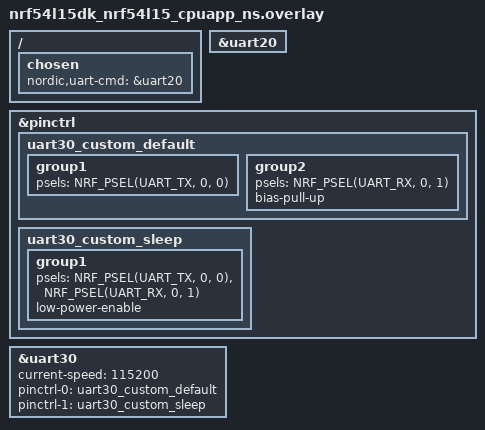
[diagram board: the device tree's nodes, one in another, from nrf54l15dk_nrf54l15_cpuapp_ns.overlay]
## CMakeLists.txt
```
#
# Copyright (c) 2019 Nordic Semiconductor ASA
#
# SPDX-License-Identifier: LicenseRef-Nordic-5-Clause
#
cmake_minimum_required(VERSION 3.20.0)

find_package(Zephyr REQUIRED HINTS $ENV{ZEPHYR_BASE})
project(mesh_shell)

include_directories(${ZEPHYR_NRF_MODULE_DIR}/samples/bluetooth/mesh/common)

# NORDIC SDK APP START
target_sources(app PRIVATE
  src/main.c
  src/model_handler.c
)
target_include_directories(app PRIVATE
  include
  ${ZEPHYR_NRF_MODULE_DIR}/samples/bluetooth/mesh/common
)

# Preinitialization related to DFU over SMP
target_sources_ifdef(CONFIG_MCUMGR_TRANSPORT_BT app PRIVATE
  ${ZEPHYR_NRF_MODULE_DIR}/samples/bluetooth/mesh/common/smp_bt.c
)

# NORDIC SDK APP END
```

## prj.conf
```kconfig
CONFIG_TEST=y
CONFIG_TEST_LOGGING_DEFAULTS=n
#CONFIG_INIT_STACKS=y
CONFIG_MAIN_STACK_SIZE=1024
CONFIG_ISR_STACK_SIZE=2048
CONFIG_SYSTEM_WORKQUEUE_STACK_SIZE=8192
CONFIG_SHELL_STACK_SIZE=2048

CONFIG_SHELL=y
CONFIG_SHELL_CMD_BUFF_SIZE=128
CONFIG_SHELL_BACKEND_SERIAL=y
CONFIG_SHELL_BACKEND_SERIAL_API_ASYNC=n
CONFIG_SHELL_BACKEND_SERIAL_API_INTERRUPT_DRIVEN=y
CONFIG_UART_INTERRUPT_DRIVEN=y


# Dummy backend to capture shell output
CONFIG_SHELL_BACKEND_DUMMY=y
CONFIG_SHELL_BACKEND_DUMMY_BUF_SIZE=1024

# Use RTT for logging and shell
CONFIG_USE_SEGGER_RTT=y
CONFIG_RTT_CONSOLE=y
CONFIG_UART_CONSOLE=n
CONFIG_SHELL_BACKEND_SERIAL=n
CONFIG_SHELL_BACKEND_RTT=y
CONFIG_LOG_BACKEND_RTT=y
CONFIG_LOG_BACKEND_UART=n
# Use different RTT channels for shell and log
CONFIG_SHELL_BACKEND_RTT_BUFFER=0
CONFIG_LOG_BACKEND_RTT_BUFFER=1

CONFIG_BT_SETTINGS=y
CONFIG_FLASH=y
CONFIG_FLASH_MAP=y
CONFIG_NVS=y
CONFIG_SETTINGS=y
# CONFIG_SECURE_STORAGE=y

CONFIG_BT=y
CONFIG_BT_OBSERVER=y
CONFIG_BT_PERIPHERAL=y
CONFIG_BT_DEVICE_NAME="Zephyr Mesh"
CONFIG_BT_GATT_CACHING=n

CONFIG_BT_CTLR_LE_ENC=n
CONFIG_BT_CTLR_LE_PING=n
CONFIG_BT_DATA_LEN_UPDATE=n
CONFIG_BT_PHY_UPDATE=n
CONFIG_BT_CTLR_MIN_USED_CHAN=n
CONFIG_BT_CTLR_PRIVACY=n
CONFIG_BT_CTLR_DTM_HCI=n
CONFIG_BT_CTLR_EXT_SCAN_FP=n
CONFIG_BT_DATA_LEN_UPDATE=n
CONFIG_BT_CTLR_PER_INIT_FEAT_XCHG=n
#CONFIG_BT_CTLR_ADVANCED_FEATURES=y
CONFIG_BT_CTLR_FILTER_ACCEPT_LIST=n

CONFIG_BT_L2CAP_TX_BUF_COUNT=4

CONFIG_BT_MESH=y
CONFIG_BT_MESH_SHELL=y
CONFIG_BT_MESH_SHELL_HEALTH_SRV_INSTANCE=y
CONFIG_BT_MESH_SHELL_PROV_CTX_INSTANCE=y
CONFIG_BT_MESH_RELAY=y
CONFIG_BT_MESH_LOW_POWER=n
CONFIG_BT_MESH_LPN_AUTO=n
CONFIG_BT_MESH_FRIEND=y
CONFIG_BT_MESH_FRIEND_QUEUE_SIZE=16
CONFIG_BT_MESH_ADV_BUF_COUNT=9
CONFIG_BT_MESH_CFG_CLI=y
CONFIG_BT_MESH_CFG_CLI_TIMEOUT=6000
CONFIG_BT_MESH_HEALTH_CLI=y
CONFIG_BT_MESH_TX_SEG_MSG_COUNT=2
CONFIG_BT_MESH_RX_SEG_MSG_COUNT=2
CONFIG_BT_MESH_RX_SEG_MAX=32
CONFIG_BT_MESH_TX_SEG_MAX=32
CONFIG_BT_MESH_CRPL=128

CONFIG_BT_MESH_PB_GATT=y
CONFIG_BT_MESH_PB_ADV=y
CONFIG_BT_MESH_GATT_PROXY=y
CONFIG_BT_MESH_NODE_ID_TIMEOUT=10

CONFIG_BT_MESH_APP_KEY_COUNT=10
# PTS requires more key slots when using Opcodes Aggregator.
# First one is implicitly taken by Device Key.
CONFIG_BT_MESH_MODEL_KEY_COUNT=10
CONFIG_BT_MESH_MODEL_GROUP_COUNT=2
CONFIG_BT_MESH_LABEL_COUNT=1

CONFIG_LOG=y
CONFIG_LOG_BUFFER_SIZE=4096
CONFIG_LOG_PROCESS_THREAD_SLEEP_MS=100
CONFIG_LOG_MODE_DEFERRED=y

CONFIG_BT_MESH_IV_UPDATE_TEST=y
CONFIG_BT_MESH_LOG_LEVEL_DBG=y
CONFIG_BT_MESH_CDB=y
CONFIG_BT_MESH_CDB_SUBNET_COUNT=10
CONFIG_BT_MESH_CDB_APP_KEY_COUNT=15
CONFIG_BT_MESH_CDB_NODE_COUNT=128
CONFIG_BT_MESH_PROVISIONER=y
CONFIG_BT_MESH_STATISTIC=y

#Added includes
CONFIG_DK_LIBRARY=y
CONFIG_BT_MESH_ONOFF_SRV=y
CONFIG_BT_MESH_ONOFF_CLI=y


#for UART
CONFIG_SERIAL=y
# UART30 for board-to-board command reception (UART20 is console)

# Redirect TF-M to use UART20 (shared with console), freeing UART30 for application
CONFIG_TFM_SECURE_UART20=y
CONFIG_TFM_SECURE_UART30=n
CONFIG_NRF_UARTE30_SECURE=n
CONFIG_UART_30_INTERRUPT_DRIVEN=y
```

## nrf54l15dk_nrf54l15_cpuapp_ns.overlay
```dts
/*
 * UART30 overlay for board-to-board command communication
 * Keep UART20 for console/debug
 * Hardware flow control (RTS/CTS) disabled for simple 2-wire UART
 */

 &uart20{
	status = "okay";
 };

&pinctrl {
	uart30_custom_default: uart30_custom_default {
		group1 {
			psels = <NRF_PSEL(UART_TX, 0, 0)>;
		};
		group2 {
			psels = <NRF_PSEL(UART_RX, 0, 1)>;
			bias-pull-up;
		};
	};

	uart30_custom_sleep: uart30_custom_sleep {
		group1 {
			psels = <NRF_PSEL(UART_TX, 0, 0)>,
				<NRF_PSEL(UART_RX, 0, 1)>;
			low-power-enable;
		};
	};
};

&uart30 {
	status = "okay";
	current-speed = <115200>;
	pinctrl-0 = <&uart30_custom_default>;
	pinctrl-1 = <&uart30_custom_sleep>;
	pinctrl-names = "default", "sleep";
};

/ {
	chosen {
		nordic,uart-cmd = &uart20;
	};
};
```

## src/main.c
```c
/*
 * Copyright (c) 2017 Intel Corporation
 *
 * SPDX-License-Identifier: Apache-2.0
 */

#include <zephyr/sys/printk.h>
#include <zephyr/console/console.h>
#include <zephyr/kernel.h>
#include <zephyr/bluetooth/bluetooth.h>
#include <bluetooth/mesh/models.h>
#include <bluetooth/mesh/dk_prov.h>
#include <dk_buttons_and_leds.h>
#include <zephyr/shell/shell.h>
#include <zephyr/shell/shell_uart.h>
#include <zephyr/shell/shell_dummy.h>
#include <zephyr/bluetooth/mesh/shell.h>
#include "model_handler.h"
#include "init.h"
#include "uart_cmd.h"
#include "log_capture.h"
//#include "filtering.h"
#include "smp_bt.h"

/*ADDED INCLUDES*/
#include <zephyr/settings/settings.h>
#include <zephyr/drivers/uart.h>
#include <zephyr/logging/log_backend.h>
#include <zephyr/logging/log_output.h>
#include <zephyr/logging/log_ctrl.h>
#include <zephyr/sys/ring_buffer.h>
#include <string.h>
#include <stdio.h>

#if defined(CONFIG_SETTINGS)
#include <zephyr/settings/settings.h>
#endif



int main(void)
{
    int err;
    printk("Initializing...\n");
    err = bt_enable(bt_ready);
    if (err && err != -EALREADY) {
        printk("Bluetooth init failed (err %d)\n", err);
    }
    err = uart_cmd_init();
    if (err) {
        printk("UART command init failed (err %d)\n", err);
    }
    log_capture_init();
    printk("Press the <Tab> button for supported commands.\n");
    printk("Before any Mesh commands you must run \"mesh init\"\n");
    printk("Ready to receive commands via UART...\n");
    while (1) {
        k_sleep(K_FOREVER);
    }
    return 0;
}
```

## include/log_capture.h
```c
#ifndef LOG_CAPTURE_H
#define LOG_CAPTURE_H

#include <zephyr/sys/ring_buffer.h>
#include <zephyr/logging/log_backend.h>
#include <stddef.h>
#include <stdint.h>
#include <stdbool.h>

#ifdef __cplusplus
extern "C" {
#endif

bool log_capture_has_logs(void);
void log_capture_init(void);
void log_capture_enable(bool enable);
size_t strip_ansi_escapes(const char *src, size_t src_len, char *dst, size_t dst_size);
void log_backend_capture_init(const struct log_backend *const backend);
bool log_capture_has_logs(void);

#ifdef __cplusplus
}
#endif

#endif // LOG_CAPTURE_H
```

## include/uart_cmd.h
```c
#ifndef UART_CMD_H
#define UART_CMD_H

#include <zephyr/drivers/uart.h>
#include <zephyr/kernel.h>

#ifdef __cplusplus
extern "C" {
#endif

void uart_cmd_buffer_init(const struct device *uart_dev);
void uart_cmd_receive_char(uint8_t c);
void uart_cmd_process(void);
void uart30_send(const char *data, const char *subject);


#ifdef __cplusplus
}
#endif

#endif // UART_CMD_H
```

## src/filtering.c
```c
/* Filtering the data received on the UART30*/
/* Strip ANSI escape sequences and shell prompt from a buffer */
static size_t strip_ansi_escapes(const char *src, size_t src_len, char *dst, size_t dst_size)
{
	size_t dst_pos = 0;
	size_t i = 0;

	while (i < src_len && dst_pos < dst_size - 1) {
		/* Check for ESC character (0x1B) */
		if (src[i] == 0x1b) {
			i++;
			if (i < src_len && src[i] == '[') {
				/* CSI sequence: skip until we hit a letter (0x40-0x7E) */
				i++;
				while (i < src_len && (src[i] < 0x40 || src[i] > 0x7E)) {
					i++;
				}
				if (i < src_len) {
					i++; /* Skip the final character */
				}
			}
			/* Other escape types - just skip the ESC */
		} else if (src[i] == '~' && i + 2 < src_len && src[i+1] == '$' && src[i+2] == ' ') {
			/* Skip shell prompt "~$ " */
			i += 3;
		} else if (src[i] == '\r') {
			/* Skip carriage return */
			i++;
		} else {
			dst[dst_pos++] = src[i++];
		}
	}
	dst[dst_pos] = '\0';
	return dst_pos;
}
```

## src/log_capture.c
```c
#include "log_capture.h"
#include <zephyr/sys/ring_buffer.h>
#include <stdbool.h>
#include <stddef.h>
#include <stdint.h>
#include <string.h>

#define LOG_CAPTURE_BUF_SIZE 256
static uint8_t log_capture_buffer[LOG_CAPTURE_BUF_SIZE];
static struct ring_buf log_ringbuf;
static bool log_capture_enabled = false;

bool log_capture_has_logs(void) {
    return ring_buf_size_get(&log_ringbuf) > 0;
}

void log_capture_init(void) {
    ring_buf_init(&log_ringbuf, LOG_CAPTURE_BUF_SIZE, log_capture_buffer);
    log_capture_enabled = false;
}

void log_capture_enable(bool enable) {
    log_capture_enabled = enable;
}

// Log backend API callback for Zephyr logging system
void log_backend_capture_init(const struct log_backend *const backend) {
    ARG_UNUSED(backend);
    log_capture_init();
}

size_t strip_ansi_escapes(const char *src, size_t src_len, char *dst, size_t dst_size) {
    size_t dst_pos = 0;
    size_t i = 0;
    while (i < src_len && dst_pos < dst_size - 1) {
        if (src[i] == 0x1b) {
            i++;
            if (i < src_len && src[i] == '[') {
                i++;
                while (i < src_len && ((src[i] < '@' || src[i] > '~'))) {
                    i++;
                }
                if (i < src_len) i++;
            }
        } else if (src[i] == '~' && i + 2 < src_len && src[i+1] == '$' && src[i+2] == ' ') {
            i += 3;
        } else if (src[i] == '\r') {
            i++;
        } else {
            dst[dst_pos++] = src[i++];
        }
    }
    dst[dst_pos] = '\0';
    return dst_pos;
}
```

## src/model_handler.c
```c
#include <zephyr/bluetooth/bluetooth.h>
#include <bluetooth/mesh/models.h>
#include <bluetooth/mesh/gen_onoff_cli.h>
#include <errno.h>
#include <stdio.h>
#include <zephyr/sys/printk.h>
#include "uart_cmd.h"

/*ADDED INCLUDES*/
#include <zephyr/shell/shell.h>
#include <zephyr/bluetooth/mesh/shell.h>

static struct bt_mesh_cfg_cli cfg_cli;

static void OnOff_status_cb(struct bt_mesh_onoff_cli *cli,
                            struct bt_mesh_msg_ctx *ctx,
                            const struct bt_mesh_onoff_status *status)
{
	(void)cli;

	if (!ctx || !status) {
		printk("OnOff status callback received invalid data\n");
		return;
	}

	printk("OnOff status from 0x%04x: status=%u",
	       ctx->addr,
	       status->present_on_off ? 1U : 0U);

	if (status->remaining_time >= 0) {
		printk(", target=%u, remaining=%ld ms",
		       status->target_on_off ? 1U : 0U,
		       (long)status->remaining_time);
	}

	printk("\n");

	char status_msg[96];
	snprintf(status_msg, sizeof(status_msg),
	         "src=0x%04x status=%s",
	         ctx->addr,
	         status->present_on_off ? "ON" : "OFF");
	uart30_send(status_msg, "OnOff_status");
}

static struct bt_mesh_onoff_cli onoff_cli = BT_MESH_ONOFF_CLI_INIT(OnOff_status_cb);

#if defined(CONFIG_BT_MESH_DFD_SRV)
static struct bt_mesh_dfd_srv dfd_srv;
#endif

#if defined(CONFIG_BT_MESH_SAR_CFG_CLI)
static struct bt_mesh_sar_cfg_cli sar_cfg_cli;
#endif

#if defined(CONFIG_BT_MESH_PRIV_BEACON_CLI)
static struct bt_mesh_priv_beacon_cli priv_beacon_cli;
#endif

#if defined(CONFIG_BT_MESH_SOL_PDU_RPL_CLI)
static struct bt_mesh_sol_pdu_rpl_cli srpl_cli;
#endif


#if defined(CONFIG_BT_MESH_OD_PRIV_PROXY_CLI)
static struct bt_mesh_od_priv_proxy_cli od_priv_proxy_cli;
#endif

#if defined(CONFIG_BT_MESH_LARGE_COMP_DATA_CLI)
struct bt_mesh_large_comp_data_cli large_comp_data_cli;
#endif

#if defined(CONFIG_BT_MESH_BRG_CFG_CLI)
static struct bt_mesh_brg_cfg_cli brg_cfg_cli;
#endif

BT_MESH_SHELL_HEALTH_PUB_DEFINE(health_pub);

static const struct bt_mesh_model root_models[] = {
	BT_MESH_MODEL_CFG_SRV,
	BT_MESH_MODEL_CFG_CLI(&cfg_cli),
	BT_MESH_MODEL_ONOFF_CLI(&onoff_cli),
	BT_MESH_MODEL_HEALTH_SRV(&bt_mesh_shell_health_srv, &health_pub, health_srv_meta),
	BT_MESH_MODEL_HEALTH_CLI(&bt_mesh_shell_health_cli),
#if defined(CONFIG_BT_MESH_DFD_SRV)
	BT_MESH_MODEL_DFD_SRV(&dfd_srv),
#else
#if defined(CONFIG_BT_MESH_SHELL_DFU_SRV)
	BT_MESH_MODEL_DFU_SRV(&bt_mesh_shell_dfu_srv),
#elif defined(CONFIG_BT_MESH_SHELL_BLOB_SRV)
	BT_MESH_MODEL_BLOB_SRV(&bt_mesh_shell_blob_srv),
#endif
#if defined(CONFIG_BT_MESH_SHELL_DFU_CLI)
	BT_MESH_MODEL_DFU_CLI(&bt_mesh_shell_dfu_cli),
#elif defined(CONFIG_BT_MESH_SHELL_BLOB_CLI)
	BT_MESH_MODEL_BLOB_CLI(&bt_mesh_shell_blob_cli),
#endif
#endif /* CONFIG_BT_MESH_DFD_SRV */
#if defined(CONFIG_BT_MESH_SHELL_RPR_CLI)
	BT_MESH_MODEL_RPR_CLI(&bt_mesh_shell_rpr_cli),
#endif
#if defined(CONFIG_BT_MESH_RPR_SRV)
	BT_MESH_MODEL_RPR_SRV,
#endif

#if defined(CONFIG_BT_MESH_SAR_CFG_SRV)
	BT_MESH_MODEL_SAR_CFG_SRV,
#endif
#if defined(CONFIG_BT_MESH_SAR_CFG_CLI)
	BT_MESH_MODEL_SAR_CFG_CLI(&sar_cfg_cli),
#endif

#if defined(CONFIG_BT_MESH_OP_AGG_SRV)
	BT_MESH_MODEL_OP_AGG_SRV,
#endif
#if defined(CONFIG_BT_MESH_OP_AGG_CLI)
	BT_MESH_MODEL_OP_AGG_CLI,
#endif

#if defined(CONFIG_BT_MESH_LARGE_COMP_DATA_SRV)
	BT_MESH_MODEL_LARGE_COMP_DATA_SRV,
#endif
#if defined(CONFIG_BT_MESH_LARGE_COMP_DATA_CLI)
	BT_MESH_MODEL_LARGE_COMP_DATA_CLI(&large_comp_data_cli),
#endif

#if defined(CONFIG_BT_MESH_PRIV_BEACON_SRV)
	BT_MESH_MODEL_PRIV_BEACON_SRV,
#endif
#if defined(CONFIG_BT_MESH_PRIV_BEACON_CLI)
	BT_MESH_MODEL_PRIV_BEACON_CLI(&priv_beacon_cli),
#endif
#if defined(CONFIG_BT_MESH_OD_PRIV_PROXY_CLI)
	BT_MESH_MODEL_OD_PRIV_PROXY_CLI(&od_priv_proxy_cli),
#endif
#if defined(CONFIG_BT_MESH_SOL_PDU_RPL_CLI)
	BT_MESH_MODEL_SOL_PDU_RPL_CLI(&srpl_cli),
#endif
#if defined(CONFIG_BT_MESH_OD_PRIV_PROXY_SRV)
	BT_MESH_MODEL_OD_PRIV_PROXY_SRV,
#endif
#if defined(CONFIG_BT_MESH_BRG_CFG_SRV)
	BT_MESH_MODEL_BRG_CFG_SRV,
#endif
#if defined(CONFIG_BT_MESH_BRG_CFG_CLI)
	BT_MESH_MODEL_BRG_CFG_CLI(&brg_cfg_cli),
#endif
};

static const struct bt_mesh_elem elements[] = {
	BT_MESH_ELEM(0, root_models, BT_MESH_MODEL_NONE),
};


static const struct bt_mesh_comp comp = {
	.cid = CONFIG_BT_COMPANY_ID,
	.elem = elements,
	.elem_count = ARRAY_SIZE(elements),
};

const struct bt_mesh_comp *model_handler_init(void)
{
	return &comp;
}

int model_handler_onoff_set(uint16_t net_idx, uint16_t app_idx, uint16_t dst_addr, bool on_off)
{
	struct bt_mesh_msg_ctx ctx = {
		.net_idx = net_idx,
		.app_idx = app_idx,
		.addr = dst_addr,
		.send_ttl = BT_MESH_TTL_DEFAULT,
	};
	struct bt_mesh_onoff_set set = {
		.on_off = on_off,
		.reuse_transaction = false,
		.transition = NULL,
	};

	if (!bt_mesh_is_provisioned()) {
		return -EAGAIN;
	}

	return bt_mesh_onoff_cli_set_unack(&onoff_cli, &ctx, &set);
}
```

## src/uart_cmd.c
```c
#include "uart_cmd.h"
//#include <_mingw_stat64.h>
#include <stdbool.h>
#include <stdint.h> //vet ikke om trengs
#include <zephyr/kernel.h>
#include <zephyr/drivers/uart.h>
#include <zephyr/sys/printk.h>
#include <zephyr/shell/shell.h>
#include <zephyr/shell/shell_dummy.h>
#include <string.h>
#include <stdio.h>
#include "log_capture.h"
#include "model_handler.h"

//kanskje
#include <zephyr/bluetooth/mesh.h>
#if defined(CONFIG_BT_MESH_SHELL)
#include <zephyr/bluetooth/mesh/shell.h>
#endif


#define CMD_BUFFER_SIZE 128
#define CMD_QUEUE_LEN   32
#define RX_CMD_QUEUE_LEN 32
#define ONOFF_STATUS_GROUP_ADDR 0xC000
//static char *cmd_buffer[CMD_BUFFER_SIZE];
//static int *cmd_buffer_pos = 0;
//static K_SEM_DEFINE(cmd_sem, 0, 1);
//static K_SEM_DEFINE(cmd_count_sem, 0, CMD_BUFFER_SIZE);
static const struct device *uart_dev;
K_MSGQ_DEFINE(cmd_msgq, CMD_BUFFER_SIZE, CMD_QUEUE_LEN, 4);
K_MSGQ_DEFINE(rx_cmd_msgq, CMD_BUFFER_SIZE, RX_CMD_QUEUE_LEN, 4);

static const char *commands[] = {
    "init", // format: init
    "scan", // format: scan
    "provandconfig", // format: provandconfig <uuid> <net_idx> <app_idx>
    "light", // format: light_on <net_idx> <app_idx> <dst_addr> <on/off>
    "cdb", // format: cdb, Function for getting cdb show
    NULL
};

static char *uuids_cur_scan[32];
static int num_uuids_cur_scan = 0;

const uint16_t net_idx = 0x0000;
static uint16_t cur_app_idx = 0;
static uint16_t app_idx_list[10] = { [0 ... 9] = 0xFFFF}; //keep track of created app_idx for checking if app_idx exist when provisioning new devices, max 10 appkeys for simplicity
static int prov_count = 0x0001;
static uint16_t local_addr;


static void run_command(const char *command);
void uart30_send(const char *data, const char *subject);
static bool enqueue_command(const char *cmd); 

static void uuid_to_str(const uint8_t uuid[16], char *out, size_t out_len)
{
    static const char hex[] = "0123456789abcdef";
    size_t p = 0;

    for (size_t i = 0; i < 16 && (p + 2) < out_len; i++) {
        out[p++] = hex[(uuid[i] >> 4) & 0x0F];
        out[p++] = hex[uuid[i] & 0x0F];
    }

    if (p < out_len) {
        out[p] = '\0';
    } else if (out_len > 0) {
        out[out_len - 1] = '\0';
    }
}


static void uart_unprov_beacon_cb(const uint8_t uuid[16],
                                  bt_mesh_prov_oob_info_t oob_info,
                                  uint32_t *uri_hash){
    char uuid_str[33];
    char line[128];

    uuid_to_str(uuid, uuid_str, sizeof(uuid_str));

    printk("uuid=%s\r\n", uuid_str);

    for (int i = 0; i < num_uuids_cur_scan; i++) {
        if (strcmp(uuids_cur_scan[i], uuid_str) == 0) {
            return;
        }
    }
    if (num_uuids_cur_scan < 32) {
        uuids_cur_scan[num_uuids_cur_scan++] = strdup(uuid_str);
    }

    snprintf(line, sizeof(line), "%s", uuid_str);
    uart30_send(line, "UUID");
}

static void uart_node_added_cb(uint16_t net_idx,
                               const uint8_t uuid[16],
                               uint16_t addr,
                               uint8_t num_elem)
{
    char cmd[CMD_BUFFER_SIZE];
        snprintf(cmd, sizeof(cmd), "mesh target dst 0x%04x", addr);
        enqueue_command(cmd);
        snprintf(cmd, sizeof(cmd), "mesh target net %u", net_idx);
        enqueue_command(cmd);
        snprintf(cmd, sizeof(cmd), "mesh models cfg appkey add %u %u", net_idx, cur_app_idx);
        enqueue_command(cmd);
        for (int i = 0; i < num_elem; i++) {
            snprintf(cmd, sizeof(cmd), "mesh models cfg model app-bind 0x%04x %u 0x1000", addr + i, cur_app_idx);
            enqueue_command(cmd);
            /* Configure Generic OnOff Server publications to a shared group address. */
            snprintf(cmd, sizeof(cmd), "mesh models cfg model pub 0x%04x 0x1000 0x%04x %u 0 7 0 0 0 0", addr + i, ONOFF_STATUS_GROUP_ADDR, cur_app_idx);
            enqueue_command(cmd);
            prov_count += 1;
        }

        char response[128];
        snprintf(response, sizeof(response), "Binding complete on app_idx %u and net_idx %u on addresses 0x%04x-0x%04x", cur_app_idx, net_idx, addr, addr+num_elem-1);
        uart30_send(response, "Provisioning");
}

static bool enqueue_command(const char *cmd)
{
    if (!cmd || cmd[0] == '\0') {
        return false;
    }

    char tmp[CMD_BUFFER_SIZE];
    snprintf(tmp, sizeof(tmp), "%s", cmd);

    if (k_msgq_put(&cmd_msgq, tmp, K_NO_WAIT) != 0) {
        printk("Command queue full, dropping: %s\n", tmp);
        const char *response = "ERROR: Command queue full";
        uart30_send(response, "Error");
        return false;
    }
    return true;
}

size_t strip_ansi_escapes(const char *src, size_t src_len, char *dst, size_t dst_size) {
    size_t dst_pos = 0;
    size_t i = 0;
    while (i < src_len && dst_pos < dst_size - 1) {
        if (src[i] == 0x1b) {
            i++;
            if (i < src_len && src[i] == '[') {
                i++;
                while (i < src_len && ((src[i] < '@' || src[i] > '~'))) {
                    i++;
                }
                if (i < src_len) i++;
            }
        } else if (src[i] == '~' && i + 2 < src_len && src[i+1] == '$' && src[i+2] == ' ') {
            i += 3;
        } else if (src[i] == '\r') {
            i++;
        } else {
            dst[dst_pos++] = src[i++];
        }
    }
    dst[dst_pos] = '\0';
    return dst_pos;
}

void uart30_send(const char *data, const char *subject)
{
    if (!uart_dev || !device_is_ready(uart_dev)) {
        return;
    }
    char json_buf[1024];
    snprintf(json_buf, sizeof(json_buf), "%s %s",subject, data);
    size_t json_len = strip_ansi_escapes(json_buf, strlen(json_buf), json_buf, sizeof(json_buf));
    for (size_t i = 0; i < json_len; i++) {
        uart_poll_out(uart_dev, json_buf[i]);
        if(json_buf[i] == '\n') {
            for (int i = 0; i < strlen(subject); i++) {
                uart_poll_out(uart_dev, subject[i]);

            }
            uart_poll_out(uart_dev, ' ');
        }
    }
    uart_poll_out(uart_dev, '\n');
}

//receives uart commands from uart and runs them
static void uart_isr(const struct device *dev, void *user_data)
{
    ARG_UNUSED(user_data);

    static char uart_buffer[CMD_BUFFER_SIZE];
    static size_t uart_buffer_pos = 0;
    uint8_t c;
    if (!uart_irq_update(dev)) {
        return;
    }
    if (!uart_irq_rx_ready(dev)) {
        return;
    }
    while (uart_fifo_read(dev, &c, 1) == 1) {
        if (c == '\r' || c == '\n') {
            if (uart_buffer_pos > 0) {
                //check if the command is in the list of allowed commands
                //printk("Received command: %s\n", uart_buffer);
                //run_command(uart_buffer);
                (void)k_msgq_put(&rx_cmd_msgq, uart_buffer, K_NO_WAIT);
                uart_buffer_pos = 0;
                memset(uart_buffer, 0, sizeof(uart_buffer));
            }else {
                printk("Received empty command, ignoring\n");
            }

        } else if (uart_buffer_pos < CMD_BUFFER_SIZE - 1) {
            uart_buffer[uart_buffer_pos++] = (char)c;
            //printk("Received char: %c\n", c);
        } else {
            printk("Command buffer overflow, resetting\n");
            uart_buffer_pos = 0;
            memset(uart_buffer, 0, sizeof(uart_buffer));
        }
    }
}

void add_appkey(uint16_t app_idx, char app_key[32]) {

    enqueue_command("mesh target net 0");
    enqueue_command("mesh target dst local");
    char cmd[96];
    if (app_key && app_key[0] != '\0') {
        snprintf(cmd, sizeof(cmd), "mesh cdb app-key-add %u %u %s", net_idx, app_idx, app_key);
    } else {
        snprintf(cmd, sizeof(cmd), "mesh cdb app-key-add %u %u", net_idx, app_idx);
    }
    enqueue_command(cmd);
    snprintf(cmd, sizeof(cmd), "mesh models cfg appkey add %u %u", net_idx, app_idx);
    enqueue_command(cmd);
    snprintf(cmd, sizeof(cmd), "mesh models cfg model app-bind 0x%04x %u 0x1001", local_addr, app_idx);
    enqueue_command(cmd);
    //add appkey to list of app_idx
    for (int i = 0; i < ARRAY_SIZE(app_idx_list); i++) {
        if (app_idx_list[i] == 0xFFFF) {
            app_idx_list[i] = app_idx;
            break;
        }
    }
    
}


static void run_command(const char *command)
{
    static bool scanning = false;
    printk("received command: %s\n", command);
    if (strcmp(command, "init") == 0) {
        printk("Initializing device...\n");
        enqueue_command("mesh init");
        enqueue_command("mesh cdb create");
        app_idx_list[0] = 0;
        enqueue_command("mesh prov local 0 0x0001");
        local_addr = 0x0001;
        prov_count += 1;
        add_appkey(0, NULL);
        /* Subscribe local Generic OnOff Client to status publications. */
        char cmd[CMD_BUFFER_SIZE];
        snprintf(cmd, sizeof(cmd), "mesh models cfg model sub-add 0x%04x 0x%04x 0x1001", local_addr, ONOFF_STATUS_GROUP_ADDR);
        enqueue_command(cmd);
        bt_mesh_shell_prov.node_added = uart_node_added_cb;
        const char *response = "initialization complete";
        uart30_send(response, "init_complete");
    } else if (strcmp(command, "scan") == 0) {
        scanning = !scanning;
        if (scanning) {
            printk("Scanning for devices...\n");
            const char *response = "scan started";
            uart30_send(response, "response");
            num_uuids_cur_scan = 0; // Reset UUID list for new scan
            bt_mesh_shell_prov.unprovisioned_beacon = uart_unprov_beacon_cb;
        } else {
            printk("Stopping scan...\n");
            const char *response = "scan stopped";
            uart30_send(response, "response");
            bt_mesh_shell_prov.unprovisioned_beacon = NULL;
        }
    } else if (strncmp(command, "provandconfig", strlen("provandconfig")) == 0) {
        unsigned int net_idx = 0U, app_idx = 0U;
        char uuid[33];
        if (sscanf(command, "provandconfig %32s %u %u", uuid, &net_idx, &app_idx) != 3) {
            printk("wrong formating provandconfig, Usage: provandconfig <uuid> <net_idx> <app_idx>\n");
            char response[128];
            snprintf(response, sizeof(response), "wrong formating provandconfig, Usage: provandconfig <uuid> <net_idx> <app_idx>");
            uart30_send(response, "Error");
            return;
        }
        //check if app_idx exist
        bool app_idx_exists = false;
        for (int i = 0; i < ARRAY_SIZE(app_idx_list); i++) {
            if (app_idx_list[i] == app_idx) {
                app_idx_exists = true;
                break;
            }
        }
        if (!app_idx_exists) {
            printk("AppKey index %u does not exist, creating new", app_idx);
            add_appkey(app_idx, NULL);
        }
        cur_app_idx = app_idx;
        char cmd[CMD_BUFFER_SIZE];
        snprintf(cmd, sizeof(cmd),
                 "mesh prov remote-adv %s %u 0x%04x 5", uuid, net_idx, prov_count);
        enqueue_command(cmd);

        char response[128];
        snprintf(response, sizeof(response), "Provisioning started");
        uart30_send(response, "response");
    } else if (strncmp(command, "light", strlen("light")) == 0) {
        unsigned int net_idx = 0U, app_idx = 0U, dst_addr = 0U, on_off = 0U;
        if (sscanf(command, "light %u %u %u %u", &net_idx, &app_idx, &dst_addr, &on_off) != 4) {
            printk("wrong formating light command, Usage: light <net_idx> <app_idx> <dst_addr> <on/off>\n");
            char response[128];
            snprintf(response, sizeof(response), "wrong formating light command, Usage: light <net_idx> <app_idx> <dst_addr> <on/off>");
            uart30_send(response, "Error");
            return;
        }
        int err = model_handler_onoff_set((uint16_t)net_idx,
                                          (uint16_t)app_idx,
                                          (uint16_t)dst_addr,
                                          on_off != 0U);
        char response[128];
        if (err) {
            snprintf(response, sizeof(response), "Light command failed to 0x%04x (err %d)", dst_addr, err);
            uart30_send(response, "Error");
            return;
        }
        //snprintf(response, sizeof(response), "Light command sent to 0x%04x", dst_addr);
        //uart30_send(response, "response"); //response will be sent from onoff status callback when status is received
    }else if (strncmp(command, "cdb", strlen("cdb")) == 0) {
        enqueue_command("mesh cdb show");
    }else if (strncmp(command, "replace", strlen("replace")) == 0) {
        char netkey[33] = {0};
        if (sscanf(command, "replace netkey:%32s address:%hu", netkey, &local_addr) != 2) {
            printk("wrong formating replace command, Usage: replace netkey:<netkey> address:<addr>\n");
            char response[128];
            snprintf(response, sizeof(response), "wrong formating replace command, Usage: replace netkey:<netkey> address:<addr>");
            uart30_send(response, "Error");
            return;
        }
        prov_count = local_addr + 1;
        char cmd[100];
        enqueue_command("mesh init");
        snprintf(cmd, sizeof(cmd), "mesh cdb create %s", netkey);
        enqueue_command(cmd);
        snprintf(cmd, sizeof(cmd), "mesh prov local %u 0x%04x", net_idx, local_addr);
        enqueue_command(cmd);

        bt_mesh_shell_prov.node_added = uart_node_added_cb;

        
        // Subscribe local Generic OnOff Client to status publications
        snprintf(cmd, sizeof(cmd), "mesh models cfg model sub-add 0x%04x 0x%04x 0x1001", local_addr, ONOFF_STATUS_GROUP_ADDR);
        enqueue_command(cmd);


        uart30_send("reProvisioned", "reProvisioned");
    }
    else if (strncmp(command, "add appkey", strlen("add appkey")) == 0) {
        uint16_t app_idx = 0;
        char appkey[33];
        if (sscanf(command, "add appkey 0x%x %32s", &app_idx, appkey) != 2) {
            printk("wrong formating appkey command, Usage: add appkey <app_idx> <appkey>\n");
            char response[128];
            snprintf(response, sizeof(response), "wrong formating appkey command, Usage: add appkey <app_idx> <appkey>");
            uart30_send(response, "Error");
            return;
        }
        add_appkey(app_idx, appkey);

    }
    else if(strncmp(command, "node", strlen("node")) == 0) {
        char uuid[33] = {0}, devkey[33] = {0};
        uint16_t addr = 0;
        uint8_t elements = 0;
        if(sscanf(command, "node uuid:%32s devkey:%32s address:0x%hx elements:%hhu", uuid, devkey, &addr, &elements) != 4 ) {
            printk("wrong formating node command, Usage: node uuid:<uuid> devkey:<devkey> address:<addr> elements:<elements>\n");
            char response[128];
            snprintf(response, sizeof(response), "wrong formating node command, Usage: node uuid:<uuid> devkey:<devkey> address:<addr> elements:<elements>");
            uart30_send(response, "Error");
            return;
        }
        char cmd[100];
        snprintf(cmd, sizeof(cmd), "mesh cdb node-add %32s 0x%04x %u %u %32s", uuid, addr, elements, net_idx, devkey);
        enqueue_command(cmd);
        char response[128];
        snprintf(response, sizeof(response), "node provisioned:%s", uuid);
        uart30_send(response, response);
    }
    else {
        enqueue_command(command);
        const char *response = "Command ran";
        uart30_send(response, "response");
    }
}

static void rx_cmd_router_thread(void)
{
    char rx_cmd[CMD_BUFFER_SIZE];

    while (1) {
        k_msgq_get(&rx_cmd_msgq, rx_cmd, K_FOREVER);
        run_command(rx_cmd);
    }
}
K_THREAD_DEFINE(rx_router_tid, 2048, rx_cmd_router_thread, NULL, NULL, NULL, 5, 0, 0);


static void shell_cmd_executor_thread(void)
{
    const struct shell *sh = shell_backend_dummy_get_ptr();
    char local_cmd[CMD_BUFFER_SIZE];
    while (1) {
        k_msgq_get(&cmd_msgq, local_cmd, K_FOREVER);
        printk("Running command: %s\n", local_cmd);

        //memset(cmd_buffer, 0, sizeof(cmd_buffer));
        //printk("Executing UART command: %s\n", local_cmd);
        if (sh) {
            shell_backend_dummy_clear_output(sh);
            int ret = shell_execute_cmd(sh, local_cmd);
            printk("shell_execute_cmd returned: %d\n", ret);
            size_t output_size;
            const char *output = shell_backend_dummy_get_output(sh, &output_size);
            printk("Command output: %.*s", (int)output_size, output);
            //print for debugging, possible to see all reponse and relay to cloud
            if (strcmp(local_cmd, "mesh cdb show") == 0) {
                uart30_send(output, "cdb");
            }
        } else {
            printk("Shell backend not available\n");
        }
    }
}

K_THREAD_DEFINE(shell_cmd_executor_tid, 4096, shell_cmd_executor_thread, NULL, NULL, NULL, 5, 0, 0);

int uart_cmd_init(void)
{
    int err;
    uart_dev = DEVICE_DT_GET(DT_NODELABEL(uart30));
    if (!device_is_ready(uart_dev)) {
        printk("UART command device not ready\n");
        return -ENODEV;
    }
    err = uart_irq_callback_user_data_set(uart_dev, uart_isr, NULL);
    if (err < 0) {
        if (err == -ENOTSUP) {
            printk("Interrupt-driven UART API not enabled\n");
        }
        return err;
    }
    uart_irq_rx_enable(uart_dev);
    printk("UART command reception initialized on UART30\n");
    printk("TX: P0.0, RX: P0.1, 115200 baud\n");
    return 0;
}
```
